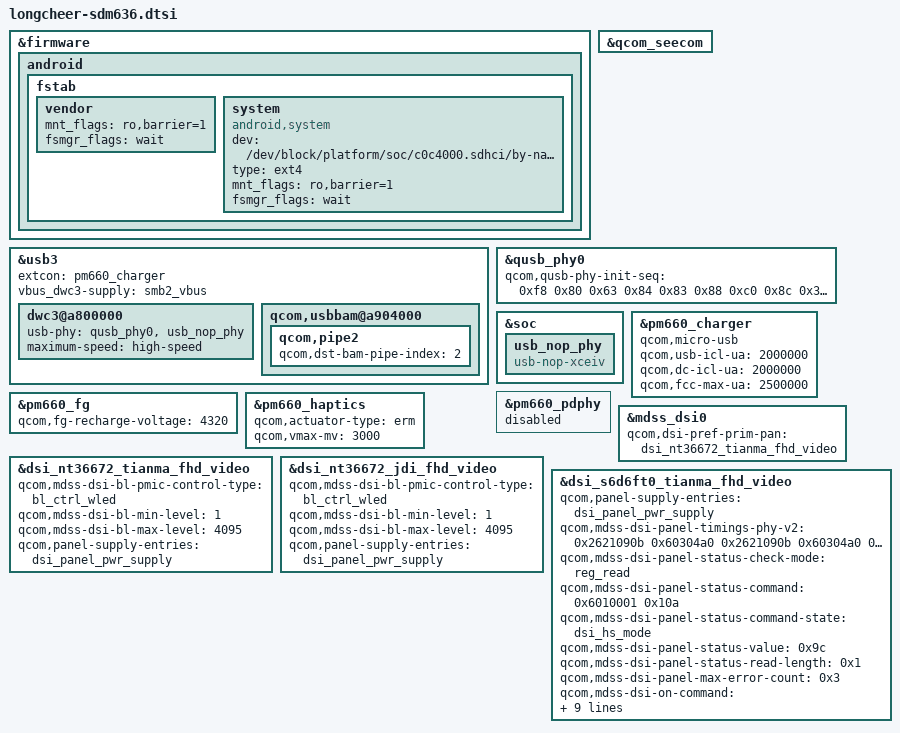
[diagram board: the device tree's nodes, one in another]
/* Copyright (c) 2019, The Linux Foundation. All rights reserved.
 *
 * This program is free software; you can redistribute it and/or modify
 * it under the terms of the GNU General Public License version 2 and
 * only version 2 as published by the Free Software Foundation.
 *
 * This program is distributed in the hope that it will be useful,
 * but WITHOUT ANY WARRANTY; without even the implied warranty of
 * MERCHANTABILITY or FITNESS FOR A PARTICULAR PURPOSE.  See the
 * GNU General Public License for more details.
 */

/* sdm660.dtsi tulip/whyred specific diff */
&firmware {
	android {
		/delete-node/ vbmeta;
		fstab {
			vendor {
				mnt_flags = "ro,barrier=1";
				fsmgr_flags = "wait";
			};

			system {
				compatible = "android,system";
				dev = "/dev/block/platform/soc/c0c4000.sdhci/by-name/system";
				type = "ext4";
				mnt_flags = "ro,barrier=1";
				fsmgr_flags = "wait";
				status = "ok";
			};
		};
	};
};

&qcom_seecom {
	/delete-property/ qcom,fde-key-size;
};


/* sdm660-common.dtsi tulip/whyred specific diff */
&usb3 {
	extcon = <&pm660_charger>;
	vbus_dwc3-supply = <&smb2_vbus>;

	dwc3@a800000 {
		usb-phy = <&qusb_phy0>, <&usb_nop_phy>;
		maximum-speed = "high-speed";
	};

	qcom,usbbam@a904000 {
		qcom,pipe2 {
			qcom,dst-bam-pipe-index = <2>;
		};
	};
};

&qusb_phy0 {
	qcom,qusb-phy-init-seq = <0xf8 0x80
				0x63 0x84
				0x83 0x88
				0xc0 0x8c
				0x30 0x08
				0x79 0x0c
				0x21 0x10
				0x14 0x9c
				0x9f 0x1c
				0x00 0x18>;
};

&soc {
	usb_nop_phy: usb_nop_phy {
		compatible = "usb-nop-xceiv";
	};
};


/* msm-pm660.dtsi tulip/whyred specific diff */
&pm660_charger {
	qcom,micro-usb;
};

&pm660_charger {
	qcom,usb-icl-ua = <2000000>;
	qcom,dc-icl-ua = <2000000>;
	qcom,fcc-max-ua = <2500000>;
};

&pm660_pdphy {
	status = "disabled";
};

&pm660_fg {
	qcom,fg-recharge-voltage = <4320>;
};

&pm660_haptics {
	qcom,actuator-type = "erm";
	qcom,vmax-mv = <3000>;
};

/* sdm636-mtp.dtsi diff */
&mdss_dsi0 {
	qcom,dsi-pref-prim-pan = <&dsi_nt36672_tianma_fhd_video>;
};

&dsi_nt36672_tianma_fhd_video {
	qcom,mdss-dsi-bl-pmic-control-type = "bl_ctrl_wled";
	qcom,mdss-dsi-bl-min-level = <1>;
	qcom,mdss-dsi-bl-max-level = <4095>;
	qcom,panel-supply-entries = <&dsi_panel_pwr_supply>;
};

&dsi_nt36672_jdi_fhd_video {
	qcom,mdss-dsi-bl-pmic-control-type = "bl_ctrl_wled";
	qcom,mdss-dsi-bl-min-level = <1>;
	qcom,mdss-dsi-bl-max-level = <4095>;
	qcom,panel-supply-entries = <&dsi_panel_pwr_supply>;
};

&dsi_s6d6ft0_tianma_fhd_video {
        qcom,panel-supply-entries = <&dsi_panel_pwr_supply>;
        qcom,mdss-dsi-panel-timings-phy-v2 = <0x2621090b 0x60304a0
                0x2621090b 0x60304a0
                0x2621090b 0x60304a0
                0x2621090b 0x60304a0
                0x2620090a 0x60304a0>;
        //qcom,esd-check-enabled;
        qcom,mdss-dsi-panel-status-check-mode = "reg_read";
        qcom,mdss-dsi-panel-status-command = <0x6010001 0x10a>;
        qcom,mdss-dsi-panel-status-command-state = "dsi_hs_mode";
        qcom,mdss-dsi-panel-status-value = <0x9c>;
        qcom,mdss-dsi-panel-status-read-length = <0x1>;
        qcom,mdss-dsi-panel-max-error-count = <0x3>;
        qcom,mdss-dsi-on-command = <0x39010000 0x39f 0xa5a50501 0x7800 0x2110005 0x1000000 0x25510 0x39010000 0x3f0 0x5a5a3901 0x0 0x2739439 0x1000000 0x3dea00 0x73111b23 0x2a405970 0x6ea18692 0x9fabb84d 0x59657f00 0x73111b23 0x2a405970 0x6ea18692 0x9fabb84d 0x59657f00 0x73111b23 0x2a405970 0x6ea18692 0x9fabb84d 0x59657f39 0x1000000 0x3deb00 0x73111b23 0x2a405970 0x6ea18692 0x9fabb84d 0x59657f00 0x73111b23 0x2a405970 0x6ea18692 0x9fabb84d 0x59657f00 0x73111b23 0x2a405970 0x6ea18692 0x9fabb84d 0x59657f39 0x1000000 0x3f0a5 0xa5050100 0x2 0x29003901 0x0 0x39f5a5a>;
        qcom,mdss-dsi-off-command = <0x39010000 0x39f 0xa5a50501 0x0 0x2280005 0x1000050 0x21000 0x39010000 0x3f0 0x5a5a3901 0x0 0x2739039 0x1000000 0x3f0a5 0xa5050100 0x2 0x24003901 0x0 0x39f5a5a>;
        qcom,mdss-dsi-on-command-state = "dsi_hs_mode";
        qcom,mdss-dsi-off-command-state = "dsi_hs_mode";
        qcom,mdss-dsi-bl-pmic-control-type = "bl_ctrl_wled";
        qcom,mdss-dsi-bl-min-level = <0x1>;
        qcom,mdss-dsi-bl-max-level = <0xfff>;
        qcom,panel-supply-entries = <&dsi_panel_pwr_supply>;
};
